# CC1350F128 register map
File version: 1.0
CPU: CM3 1.0, other endian, MPU, FPU, 3 interrupt priority bits
Registers are 32-bit, read-write, reset 0x0 unless marked. A register's access mark holds for its fields unless they carry their own. Offsets are from the block's base; [hi:lo] are bit positions; {n}, {i} and the like mark numbered series.

## GPIO — MCU GPIO - I/F for controlling and reading IO status and IO event status
Base 0x40022000
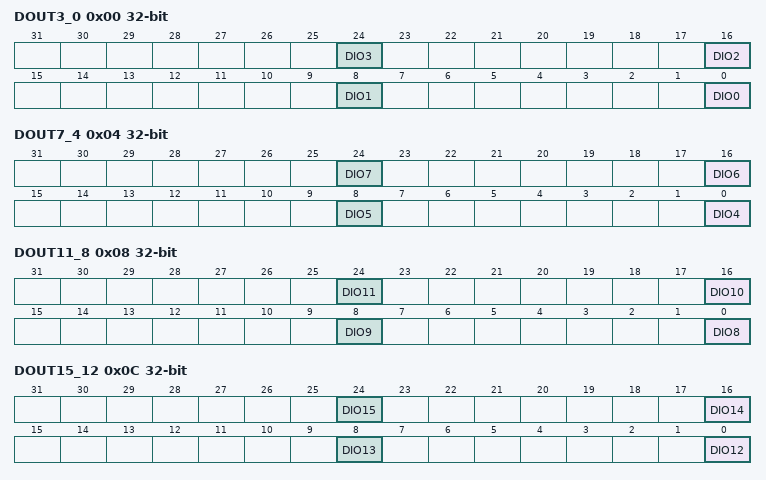
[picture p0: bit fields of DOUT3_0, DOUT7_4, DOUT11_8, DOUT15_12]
0x00 DOUT3_0 — Data Out 0 to 3 Alias register for byte access to each bit in DOUT31_0
  [8n] DIO{n} wo (n=0..3) — [{8n}:{8n}] Sets the state of the pin that is configured as DIO#{n}, if the corresponding DOE31_0 bitfield is set.
0x04 DOUT7_4 — Data Out 4 to 7 Alias register for byte access to each bit in DOUT31_0
  [8n-32] DIO{n} wo (n=4..7) — [{8n-32}:{8n-32}] Sets the state of the pin that is configured as DIO#{n}, if the corresponding DOE31_0 bitfield is set.
0x08 DOUT11_8 — Data Out 8 to 11 Alias register for byte access to each bit in DOUT31_0
  [8n-64] DIO{n} wo (n=8..11) — [{8n-64}:{8n-64}] Sets the state of the pin that is configured as DIO#{n}, if the corresponding DOE31_0 bitfield is set.
0x0C DOUT15_12 — Data Out 12 to 15 Alias register for byte access to each bit in DOUT31_0
  [8n-96] DIO{n} wo (n=12..15) — [{8n-96}:{8n-96}] Sets the state of the pin that is configured as DIO#{n}, if the corresponding DOE31_0 bitfield is set.
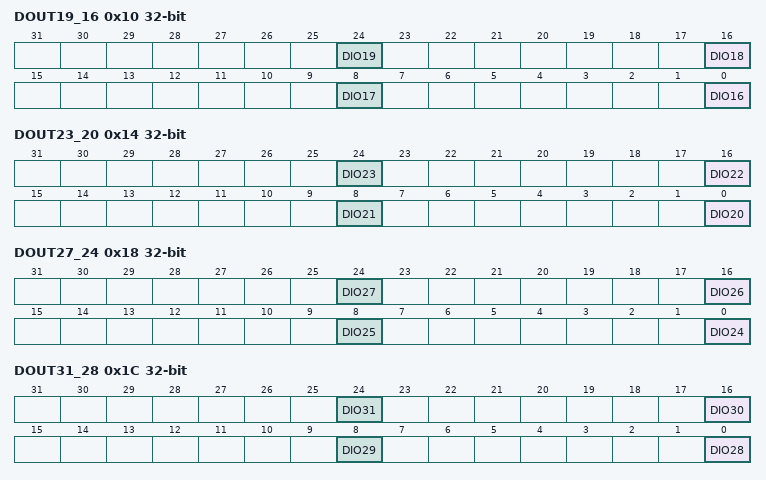
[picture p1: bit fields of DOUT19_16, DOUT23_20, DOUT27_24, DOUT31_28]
0x10 DOUT19_16 — Data Out 16 to 19 Alias register for byte access to each bit in DOUT31_0
  [8n-128] DIO{n} wo (n=16..19) — [{8n-128}:{8n-128}] Sets the state of the pin that is configured as DIO#{n}, if the corresponding DOE31_0 bitfield is set.
0x14 DOUT23_20 — Data Out 20 to 23 Alias register for byte access to each bit in DOUT31_0
  [8n-160] DIO{n} wo (n=20..23) — [{8n-160}:{8n-160}] Sets the state of the pin that is configured as DIO#{n}, if the corresponding DOE31_0 bitfield is set.
0x18 DOUT27_24 — Data Out 24 to 27 Alias register for byte access to each bit in DOUT31_0
  [8n-192] DIO{n} wo (n=24..27) — [{8n-192}:{8n-192}] Sets the state of the pin that is configured as DIO#{n}, if the corresponding DOE31_0 bitfield is set.
0x1C DOUT31_28 — Data Out 28 to 31 Alias register for byte access to each bit in DOUT31_0
  [8n-224] DIO{n} wo (n=28..31) — [{8n-224}:{8n-224}] Sets the state of the pin that is configured as DIO#{n}, if the corresponding DOE31_0 bitfield is set.
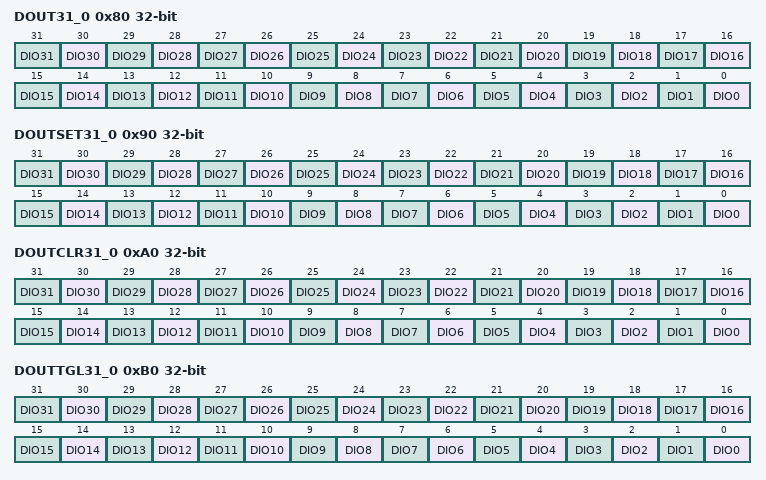
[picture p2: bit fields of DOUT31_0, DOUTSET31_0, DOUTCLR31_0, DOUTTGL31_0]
0x80 DOUT31_0 — Data Output for DIO 0 to 31
  [n] DIO{n} (n=0..31) — [{n}:{n}] Data output for DIO {n}
0x90 DOUTSET31_0 — Data Out Set Writing 1 to a bit position sets the corresponding bit in the DOUT31_0 register
  [n] DIO{n} wo (n=0..31) — [{n}:{n}] Set bit {n}
0xA0 DOUTCLR31_0 — Data Out Clear Writing 1 to a bit position clears the corresponding bit in the DOUT31_0 register
  [n] DIO{n} wo (n=0..31) — [{n}:{n}] Clears bit {n}
0xB0 DOUTTGL31_0 — Data Out Toggle Writing 1 to a bit position will invert the corresponding DIO output.
  [n] DIO{n} (n=0..31) — [{n}:{n}] Toggles bit {n}
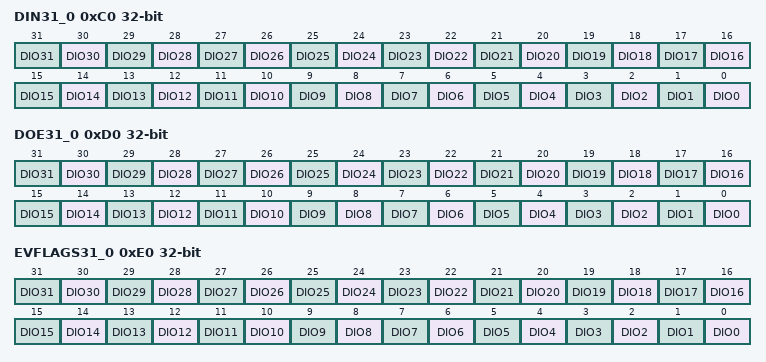
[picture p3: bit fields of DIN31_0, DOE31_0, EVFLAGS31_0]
0xC0 DIN31_0 — Data Input from DIO 0 to 31
  [n] DIO{n} ro (n=0..31) — [{n}:{n}] Data input from DIO {n}
0xD0 DOE31_0 — Data Output Enable for DIO 0 to 31
  [n] DIO{n} (n=0..31) — [{n}:{n}] Data output enable for DIO {n}
0xE0 EVFLAGS31_0 — Event Register for DIO 0 to 31 Reading this registers will return 1 for triggered event and 0 for non-triggered events. Writing a 1 to a bit field will clear the event. The configuration of events is done inside MCU IOC, e.g. events for DIO #0 is configured in IOC:IOCFG0.EDGE_DET and IOC:IOCFG0.EDGE_IRQ_EN.
  [n] DIO{n} (n=0..31) — [{n}:{n}] Event for DIO {n}

## RFC_PWR — RF Core Power Management
Base 0x40040000
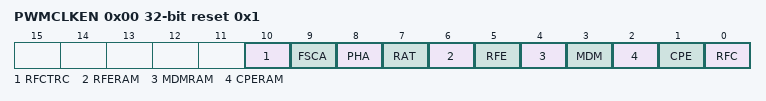
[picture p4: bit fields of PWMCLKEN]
0x00 PWMCLKEN reset 0x1 — RF Core Power Management and Clock Enable
  [10] RFCTRC — [10:10] Enable clock to the RF Core Tracer (RFCTRC) module.
  [9] FSCA — [9:9] Enable clock to the Frequency Synthesizer Calibration Accelerator (FSCA) module.
  [8] PHA — [8:8] Enable clock to the Packet Handling Accelerator (PHA) module.
  [7] RAT — [7:7] Enable clock to the Radio Timer (RAT) module.
  [6] RFERAM — [6:6] Enable clock to the RF Engine RAM module.
  [5] RFE — [5:5] Enable clock to the RF Engine (RFE) module.
  [4] MDMRAM — [4:4] Enable clock to the Modem RAM module.
  [3] MDM — [3:3] Enable clock to the Modem (MDM) module.
  [2] CPERAM — [2:2] Enable clock to the Command and Packet Engine (CPE) RAM module. As part of RF Core initialization, set this bit together with CPE bit to enable CPE to boot.
  [1] CPE — [1:1] Enable processor clock (hclk) to the Command and Packet Engine (CPE). As part of RF Core initialization, set this bit together with CPERAM bit to enable CPE to boot.
  [0] RFC ro — [0:0] Enable essential clocks for the RF Core interface. This includes the interconnect, the radio doorbell DBELL command interface, the power management (PWR) clock control module, and bus clock (sclk) for the CPE. To remove possibility of locking yourself out from the RF Core, this bit can not be cleared. If you need to disable all clocks to the RF Core, see the PRCM:RFCCLKG.CLK_EN register.
